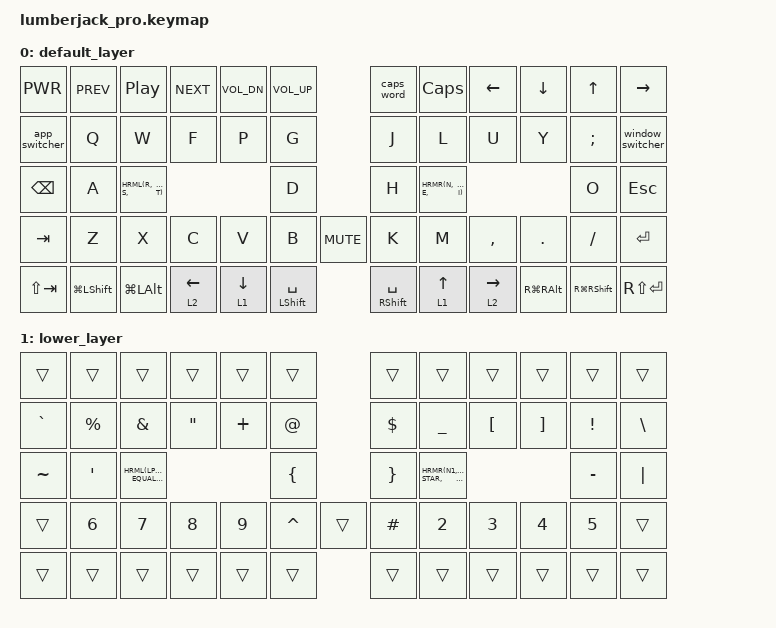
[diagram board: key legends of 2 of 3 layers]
/*
 * Copyright (c) 2021 The ZMK Contributors
 *
 * SPDX-License-Identifier: MIT
 */

#include <behaviors.dtsi>
#include <dt-bindings/zmk/bt.h>
#include <dt-bindings/zmk/keys.h>

#define BASE 0
#define LOWER 1
#define RAISE 2
#define HRML(k1,k2,k3) &mt LCTRL k1  &mt LALT k2  &mt LGUI k3
#define HRMR(k1,k2,k3) &mt RGUI k1  &mt RALT k2  &mt RCTRL k3

/* Uncomment to enable the encoder */
&sensors { status = "okay"; };
&encoder { status = "okay"; };

/ {
    macros {
        app_switcher: app_switcher {
            compatible = "zmk,behavior-macro";
            #binding-cells = <0>;
            bindings =
                <&macro_press>,
                <&kp LCMD>,
                <&macro_tap>,
                <&kp TAB>,
                <&macro_tap>,
                <&sk LCMD>,
                <&macro_release>,
                <&kp LCMD>;

            tap-ms = <10>;
            wait-ms = <50>;
        };

        window_switcher: window_switcher {
            compatible = "zmk,behavior-macro";
            #binding-cells = <0>;
            bindings =
                <&macro_press>,
                <&kp LALT>,
                <&macro_tap>,
                <&kp TAB>,
                <&macro_tap>,
                <&sk LALT>,
                <&macro_release>,
                <&kp LALT>;

            tap-ms = <10>;
            wait-ms = <50>;
        };
    };

    behaviors {
        mt: mod_tap {
                label = "hold_tap";
                compatible = "zmk,behavior-hold-tap";
                #binding-cells = <2>;
                flavor = "tap-preferred";
                tapping-term-ms = <220>;
                quick-tap-ms = <150>;
                global-quick-tap;
                bindings = <&kp>, <&kp>;
            };
    };

    keymap {
        compatible = "zmk,keymap";

        default_layer {
            bindings = <
&kp C_PWR      &kp C_PREV       &kp C_PP            &kp C_NEXT      &kp C_VOL_DN       &kp C_VOL_UP                      &caps_word             &kp CAPS             &kp LEFT         &kp DOWN             &kp UP         &kp RIGHT
&app_switcher   &kp Q            &kp W               &kp F           &kp P              &kp G                             &kp J                  &kp L                &kp U            &kp Y                &kp SEMICOLON  &window_switcher
&kp BACKSPACE  &kp A            HRML(R,             S,              T)                 &kp D                             &kp H                  HRMR(N,              E,               I)                   &kp O          &kp ESCAPE
&kp TAB        &kp Z            &kp X               &kp C           &kp V              &kp B                 &kp C_MUTE  &kp K                  &kp M                &kp COMMA        &kp DOT              &kp FSLH       &kp RET
&kp LS(TAB)    &kp LG(LSHFT)    &kp LG(LALT)        &lt 2 LEFT      &lt 1 DOWN         &mt LEFT_SHIFT SPACE              &mt RIGHT_SHIFT SPACE  &lt 1 UP             &lt 2 RIGHT      &kp RG(RALT)         &kp RG(RSHFT)  &kp RS(ENTER)
            >;

            sensor-bindings = <&inc_dec_kp C_VOL_UP C_VOL_DN>;
        };

        lower_layer {
            bindings = <
&trans     &trans           &trans                             &trans              &trans                        &trans                  &trans           &trans                         &trans                  &trans                               &trans           &trans
&kp GRAVE  &kp PERCENT      &kp AMPERSAND                      &kp DOUBLE_QUOTES   &kp PLUS                      &kp AT_SIGN             &kp DOLLAR       &kp UNDERSCORE                 &kp LEFT_BRACKET        &kp RIGHT_BRACKET                    &kp EXCLAMATION  &kp BACKSLASH
&kp TILDE  &kp SQT          HRML(LPAR,                         EQUAL,              N0)                           &kp LEFT_BRACE          &kp RIGHT_BRACE  HRMR(N1,                       STAR,                   RPAR)                                &kp MINUS        &kp PIPE
&trans     &kp N6           &kp N7                             &kp N8              &kp N9                        &kp CARET       &trans  &kp HASH         &kp N2                         &kp N3                  &kp N4                               &kp N5           &trans
&trans     &trans           &trans                             &trans              &trans                        &trans                  &trans           &trans                         &trans                  &trans                               &trans           &trans
            >;

            sensor-bindings = <&inc_dec_kp PG_UP PG_DN>;
        };

        raise_layer {
            bindings = <
&bt BT_CLR_ALL  &trans        &trans        &trans    &trans                &trans                      &trans           &trans                &trans    &trans         &trans         &bt BT_CLR
&bt BT_SEL 0    &none         &none         &none     &none                 &none                       &none            &none                 &none     &none          &none          &bt BT_DISC 0
&bt BT_SEL 1    &kp F12       &kp LCTRL     &kp LALT  &mt LGUI F10          &none                       &none            &mt RGUI F1           &kp RALT  &kp RCTRL      &kp F11        &bt BT_DISC 1
&trans          &kp F6        &kp F7        &kp F8    &kp F9                &none             &trans    &none            &kp F2                &kp F3    &kp F4         &kp F5         &trans
&trans          &trans        &trans        &trans    &trans                &kp LEFT_SHIFT              &kp RIGHT_SHIFT  &trans                &trans    &trans         &trans         &trans
            >;

        };
    };
};
